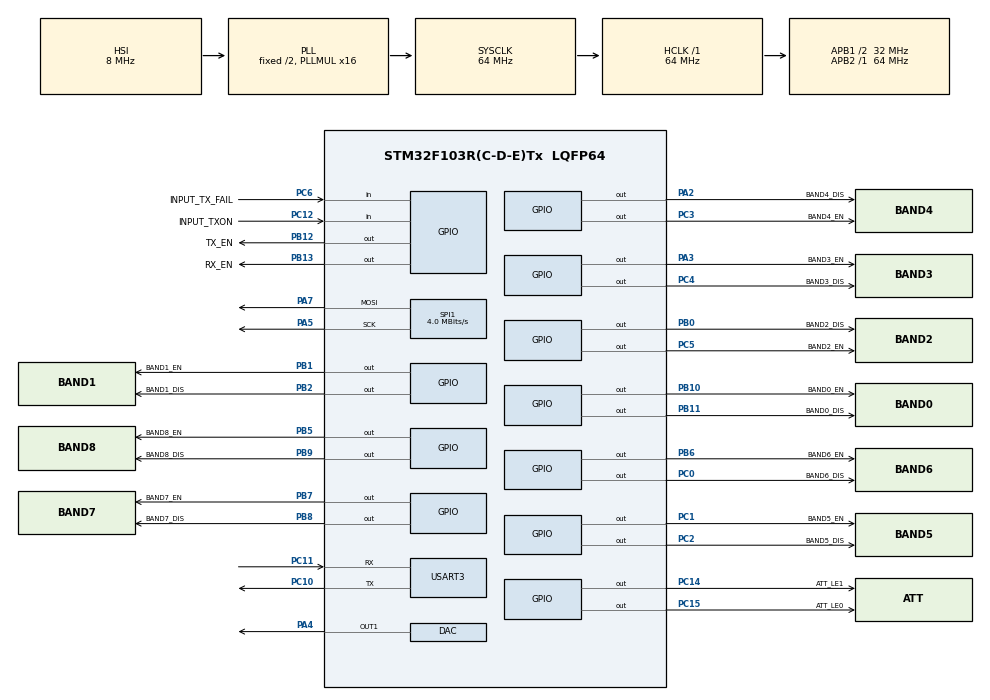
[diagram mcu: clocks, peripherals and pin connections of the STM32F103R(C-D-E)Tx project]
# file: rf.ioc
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Dma.Request0=USART3_RX
Dma.Request1=USART3_TX
Dma.USART3_RX.0.Direction=DMA_PERIPH_TO_MEMORY
Dma.USART3_RX.0.Instance=DMA1_Channel3
Dma.USART3_RX.0.MemDataAlignment=DMA_MDATAALIGN_BYTE
Dma.USART3_RX.0.MemInc=DMA_MINC_ENABLE
Dma.USART3_RX.0.Mode=DMA_CIRCULAR
Dma.USART3_RX.0.PeriphDataAlignment=DMA_PDATAALIGN_BYTE
Dma.USART3_RX.0.PeriphInc=DMA_PINC_DISABLE
Dma.USART3_RX.0.Priority=DMA_PRIORITY_LOW
Dma.USART3_TX.1.Direction=DMA_MEMORY_TO_PERIPH
Dma.USART3_TX.1.Instance=DMA1_Channel2
Dma.USART3_TX.1.MemDataAlignment=DMA_MDATAALIGN_BYTE
Dma.USART3_TX.1.MemInc=DMA_MINC_ENABLE
Dma.USART3_TX.1.Mode=DMA_NORMAL
Dma.USART3_TX.1.PeriphDataAlignment=DMA_PDATAALIGN_BYTE
Dma.USART3_TX.1.PeriphInc=DMA_PINC_DISABLE
Dma.USART3_TX.1.Priority=DMA_PRIORITY_LOW
Mcu.Family=STM32F1
Mcu.Name=STM32F103R(C-D-E)Tx
Mcu.Package=LQFP64
NVIC.DMA1_Channel2_IRQn=true\:7\:0\:true\:false\:true\:false\:true\:true
NVIC.DMA1_Channel3_IRQn=true\:7\:0\:true\:false\:true\:false\:true\:true
NVIC.PriorityGroup=NVIC_PRIORITYGROUP_4
NVIC.SPI1_IRQn=true\:6\:0\:true\:false\:true\:true\:true\:true
PA13.Mode=Trace_Asynchronous_SW
PA13.Signal=SYS_JTMS-SWDIO
PA14.Mode=Trace_Asynchronous_SW
PA14.Signal=SYS_JTCK-SWCLK
PA2.GPIO_Label=BAND4_DIS
PA2.Signal=GPIO_Output
PA3.GPIO_Label=BAND3_EN
PA3.Signal=GPIO_Output
PA4.Signal=COMP_DAC1_group
PA5.Mode=TX_Only_Simplex_Unidirect_Master
PA5.Signal=SPI1_SCK
PA7.Mode=TX_Only_Simplex_Unidirect_Master
PA7.Signal=SPI1_MOSI
PB0.GPIO_Label=BAND2_DIS
PB0.Signal=GPIO_Output
PB1.GPIO_Label=BAND1_EN
PB1.Signal=GPIO_Output
PB10.GPIO_Label=BAND0_EN
PB10.Signal=GPIO_Output
PB11.GPIO_Label=BAND0_DIS
PB11.Signal=GPIO_Output
PB12.GPIO_Label=TX_EN
PB12.GPIO_Speed=GPIO_SPEED_FREQ_HIGH
PB12.Signal=GPIO_Output
PB13.GPIO_Label=RX_EN
PB13.GPIO_Speed=GPIO_SPEED_FREQ_HIGH
PB13.Signal=GPIO_Output
PB2.GPIO_Label=BAND1_DIS
PB2.Signal=GPIO_Output
PB3.Mode=Trace_Asynchronous_SW
PB3.Signal=SYS_JTDO-TRACESWO
PB5.GPIO_Label=BAND8_EN
PB5.Signal=GPIO_Output
PB6.GPIO_Label=BAND6_EN
PB6.Signal=GPIO_Output
PB7.GPIO_Label=BAND7_EN
PB7.Signal=GPIO_Output
PB8.GPIO_Label=BAND7_DIS
PB8.Signal=GPIO_Output
PB9.GPIO_Label=BAND8_DIS
PB9.Signal=GPIO_Output
PC0.GPIO_Label=BAND6_DIS
PC0.Signal=GPIO_Output
PC1.GPIO_Label=BAND5_EN
PC1.Signal=GPIO_Output
PC10.Mode=Asynchronous
PC10.Signal=USART3_TX
PC11.Mode=Asynchronous
PC11.Signal=USART3_RX
PC12.GPIO_Label=INPUT_TXON
PC12.GPIO_PuPd=GPIO_PULLDOWN
PC12.Signal=GPIO_Input
PC14-OSC32_IN.GPIO_Label=ATT_LE1
PC14-OSC32_IN.GPIO_Speed=GPIO_SPEED_FREQ_HIGH
PC14-OSC32_IN.Signal=GPIO_Output
PC15-OSC32_OUT.GPIO_Label=ATT_LE0
PC15-OSC32_OUT.GPIO_Speed=GPIO_SPEED_FREQ_HIGH
PC15-OSC32_OUT.Signal=GPIO_Output
PC2.GPIO_Label=BAND5_DIS
PC2.Signal=GPIO_Output
PC3.GPIO_Label=BAND4_EN
PC3.Signal=GPIO_Output
PC4.GPIO_Label=BAND3_DIS
PC4.Signal=GPIO_Output
PC5.GPIO_Label=BAND2_EN
PC5.Signal=GPIO_Output
PC6.GPIO_Label=INPUT_TX_FAIL
PC6.GPIO_PuPd=GPIO_PULLDOWN
PC6.Signal=GPIO_Input
ProjectManager.HeapSize=0x200
ProjectManager.StackSize=0x400
ProjectManager.TargetToolchain=STM32CubeIDE
RCC.AHBFreq_Value=64000000
RCC.APB1CLKDivider=RCC_HCLK_DIV2
RCC.APB1Freq_Value=32000000
RCC.APB1TimFreq_Value=64000000
RCC.APB2Freq_Value=64000000
RCC.APB2TimFreq_Value=64000000
RCC.HCLKFreq_Value=64000000
RCC.PLLMUL=RCC_PLL_MUL16
RCC.SYSCLKFreq_VALUE=64000000
RCC.SYSCLKSource=RCC_SYSCLKSOURCE_PLLCLK
RCC.USBFreq_Value=64000000
SH.COMP_DAC1_group.0=DAC_OUT1,DAC_OUT1
SPI1.BaudRatePrescaler=SPI_BAUDRATEPRESCALER_16
SPI1.CalculateBaudRate=4.0 MBits/s
SPI1.Direction=SPI_DIRECTION_2LINES
SPI1.Mode=SPI_MODE_MASTER
SPI1.VirtualType=VM_MASTER
USART3.VirtualMode=VM_ASYNC
board=custom

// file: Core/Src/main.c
/* USER CODE BEGIN Header */
/**
  ******************************************************************************
  * @file           : main.c
  * @brief          : Main program body
  ******************************************************************************
  * @attention
  *
  * Copyright (c) 2025 STMicroelectronics.
  * All rights reserved.
  *
  * This software is licensed under terms that can be found in the LICENSE file
  * in the root directory of this software component.
  * If no LICENSE file comes with this software, it is provided AS-IS.
  *
  ******************************************************************************
  */
/* USER CODE END Header */
#include "main.h"

/* USER CODE BEGIN Includes */
#include "cmd.h"
#include "gpio.h"
/* USER CODE END Includes */

DAC_HandleTypeDef hdac;

SPI_HandleTypeDef hspi1;

UART_HandleTypeDef huart3;
DMA_HandleTypeDef hdma_usart3_rx;
DMA_HandleTypeDef hdma_usart3_tx;

void SystemClock_Config(void);
static void MX_GPIO_Init(void);
static void MX_DMA_Init(void);
static void MX_DAC_Init(void);
static void MX_SPI1_Init(void);
static void MX_USART3_UART_Init(void);

int main(void)
{

  /* MCU Configuration--------------------------------------------------------*/

  /* Reset of all peripherals, Initializes the Flash interface and the Systick. */
  HAL_Init();

  /* Configure the system clock */
  SystemClock_Config();

  /* Initialize all configured peripherals */
  MX_GPIO_Init();
  MX_DMA_Init();
  MX_DAC_Init();
  MX_SPI1_Init();
  MX_USART3_UART_Init();
  /* USER CODE BEGIN 2 */
  HAL_DAC_SetValue(&hdac, DAC_CHANNEL_1, DAC_ALIGN_12B_R, 0);
  HAL_DAC_Start(&hdac, DAC_CHANNEL_1);
  gpio_tx_off();
  cmd_start();
  /* USER CODE END 2 */

  /* Infinite loop */
  while (1)
  {

    /* USER CODE BEGIN 3 */
	  cmd_tick();
	  gpio_tick();
  }
  /* USER CODE END 3 */
}

void SystemClock_Config(void)
{
  RCC_OscInitTypeDef RCC_OscInitStruct = {0};
  RCC_ClkInitTypeDef RCC_ClkInitStruct = {0};

  /** Initializes the RCC Oscillators according to the specified parameters
  * in the RCC_OscInitTypeDef structure.
  */
  RCC_OscInitStruct.OscillatorType = RCC_OSCILLATORTYPE_HSI;
  RCC_OscInitStruct.HSIState = RCC_HSI_ON;
  RCC_OscInitStruct.HSICalibrationValue = RCC_HSICALIBRATION_DEFAULT;
  RCC_OscInitStruct.PLL.PLLState = RCC_PLL_ON;
  RCC_OscInitStruct.PLL.PLLSource = RCC_PLLSOURCE_HSI_DIV2;
  RCC_OscInitStruct.PLL.PLLMUL = RCC_PLL_MUL16;
  if (HAL_RCC_OscConfig(&RCC_OscInitStruct) != HAL_OK)
  {
    Error_Handler();
  }

  /** Initializes the CPU, AHB and APB buses clocks
  */
  RCC_ClkInitStruct.ClockType = RCC_CLOCKTYPE_HCLK|RCC_CLOCKTYPE_SYSCLK
                              |RCC_CLOCKTYPE_PCLK1|RCC_CLOCKTYPE_PCLK2;
  RCC_ClkInitStruct.SYSCLKSource = RCC_SYSCLKSOURCE_PLLCLK;
  RCC_ClkInitStruct.AHBCLKDivider = RCC_SYSCLK_DIV1;
  RCC_ClkInitStruct.APB1CLKDivider = RCC_HCLK_DIV2;
  RCC_ClkInitStruct.APB2CLKDivider = RCC_HCLK_DIV1;

  if (HAL_RCC_ClockConfig(&RCC_ClkInitStruct, FLASH_LATENCY_2) != HAL_OK)
  {
    Error_Handler();
  }
}

static void MX_DAC_Init(void)
{

  DAC_ChannelConfTypeDef sConfig = {0};

  /** DAC Initialization
  */
  hdac.Instance = DAC;
  if (HAL_DAC_Init(&hdac) != HAL_OK)
  {
    Error_Handler();
  }

  /** DAC channel OUT1 config
  */
  sConfig.DAC_Trigger = DAC_TRIGGER_NONE;
  sConfig.DAC_OutputBuffer = DAC_OUTPUTBUFFER_ENABLE;
  if (HAL_DAC_ConfigChannel(&hdac, &sConfig, DAC_CHANNEL_1) != HAL_OK)
  {
    Error_Handler();
  }

}

static void MX_SPI1_Init(void)
{

  /* SPI1 parameter configuration*/
  hspi1.Instance = SPI1;
  hspi1.Init.Mode = SPI_MODE_MASTER;
  hspi1.Init.Direction = SPI_DIRECTION_2LINES;
  hspi1.Init.DataSize = SPI_DATASIZE_8BIT;
  hspi1.Init.CLKPolarity = SPI_POLARITY_LOW;
  hspi1.Init.CLKPhase = SPI_PHASE_1EDGE;
  hspi1.Init.NSS = SPI_NSS_SOFT;
  hspi1.Init.BaudRatePrescaler = SPI_BAUDRATEPRESCALER_16;
  hspi1.Init.FirstBit = SPI_FIRSTBIT_MSB;
  hspi1.Init.TIMode = SPI_TIMODE_DISABLE;
  hspi1.Init.CRCCalculation = SPI_CRCCALCULATION_DISABLE;
  hspi1.Init.CRCPolynomial = 10;
  if (HAL_SPI_Init(&hspi1) != HAL_OK)
  {
    Error_Handler();
  }

}

static void MX_USART3_UART_Init(void)
{

  huart3.Instance = USART3;
  huart3.Init.BaudRate = 115200;
  huart3.Init.WordLength = UART_WORDLENGTH_8B;
  huart3.Init.StopBits = UART_STOPBITS_1;
  huart3.Init.Parity = UART_PARITY_NONE;
  huart3.Init.Mode = UART_MODE_TX_RX;
  huart3.Init.HwFlowCtl = UART_HWCONTROL_NONE;
  huart3.Init.OverSampling = UART_OVERSAMPLING_16;
  if (HAL_UART_Init(&huart3) != HAL_OK)
  {
    Error_Handler();
  }

}

static void MX_DMA_Init(void)
{

  /* DMA controller clock enable */
  __HAL_RCC_DMA1_CLK_ENABLE();

  /* DMA interrupt init */
  /* DMA1_Channel2_IRQn interrupt configuration */
  HAL_NVIC_SetPriority(DMA1_Channel2_IRQn, 7, 0);
  HAL_NVIC_EnableIRQ(DMA1_Channel2_IRQn);
  /* DMA1_Channel3_IRQn interrupt configuration */
  HAL_NVIC_SetPriority(DMA1_Channel3_IRQn, 7, 0);
  HAL_NVIC_EnableIRQ(DMA1_Channel3_IRQn);

}

static void MX_GPIO_Init(void)
{
  GPIO_InitTypeDef GPIO_InitStruct = {0};

  /* GPIO Ports Clock Enable */
  __HAL_RCC_GPIOC_CLK_ENABLE();
  __HAL_RCC_GPIOA_CLK_ENABLE();
  __HAL_RCC_GPIOB_CLK_ENABLE();

  /*Configure GPIO pin Output Level */
  HAL_GPIO_WritePin(GPIOC, ATT_LE1_Pin|ATT_LE0_Pin|BAND6_DIS_Pin|BAND5_EN_Pin
                          |BAND5_DIS_Pin|BAND4_EN_Pin|BAND3_DIS_Pin|BAND2_EN_Pin, GPIO_PIN_RESET);

  /*Configure GPIO pin Output Level */
  HAL_GPIO_WritePin(GPIOA, BAND4_DIS_Pin|BAND3_EN_Pin, GPIO_PIN_RESET);

  /*Configure GPIO pin Output Level */
  HAL_GPIO_WritePin(GPIOB, BAND2_DIS_Pin|BAND1_EN_Pin|BAND1_DIS_Pin|BAND0_EN_Pin
                          |BAND0_DIS_Pin|TX_EN_Pin|RX_EN_Pin|BAND8_EN_Pin
                          |BAND6_EN_Pin|BAND7_EN_Pin|BAND7_DIS_Pin|BAND8_DIS_Pin, GPIO_PIN_RESET);

  /*Configure GPIO pins : ATT_LE1_Pin ATT_LE0_Pin BAND6_DIS_Pin BAND5_EN_Pin
                           BAND5_DIS_Pin BAND4_EN_Pin BAND3_DIS_Pin BAND2_EN_Pin */
  GPIO_InitStruct.Pin = ATT_LE1_Pin|ATT_LE0_Pin|BAND6_DIS_Pin|BAND5_EN_Pin
                          |BAND5_DIS_Pin|BAND4_EN_Pin|BAND3_DIS_Pin|BAND2_EN_Pin;
  GPIO_InitStruct.Mode = GPIO_MODE_OUTPUT_PP;
  GPIO_InitStruct.Pull = GPIO_NOPULL;
  GPIO_InitStruct.Speed = GPIO_SPEED_FREQ_LOW;
  HAL_GPIO_Init(GPIOC, &GPIO_InitStruct);

  /*Configure GPIO pins : BAND4_DIS_Pin BAND3_EN_Pin */
  GPIO_InitStruct.Pin = BAND4_DIS_Pin|BAND3_EN_Pin;
  GPIO_InitStruct.Mode = GPIO_MODE_OUTPUT_PP;
  GPIO_InitStruct.Pull = GPIO_NOPULL;
  GPIO_InitStruct.Speed = GPIO_SPEED_FREQ_LOW;
  HAL_GPIO_Init(GPIOA, &GPIO_InitStruct);

  /*Configure GPIO pins : BAND2_DIS_Pin BAND1_EN_Pin BAND1_DIS_Pin BAND0_EN_Pin
                           BAND0_DIS_Pin TX_EN_Pin RX_EN_Pin BAND8_EN_Pin
                           BAND6_EN_Pin BAND7_EN_Pin BAND7_DIS_Pin BAND8_DIS_Pin */
  GPIO_InitStruct.Pin = BAND2_DIS_Pin|BAND1_EN_Pin|BAND1_DIS_Pin|BAND0_EN_Pin
                          |BAND0_DIS_Pin|TX_EN_Pin|RX_EN_Pin|BAND8_EN_Pin
                          |BAND6_EN_Pin|BAND7_EN_Pin|BAND7_DIS_Pin|BAND8_DIS_Pin;
  GPIO_InitStruct.Mode = GPIO_MODE_OUTPUT_PP;
  GPIO_InitStruct.Pull = GPIO_NOPULL;
  GPIO_InitStruct.Speed = GPIO_SPEED_FREQ_LOW;
  HAL_GPIO_Init(GPIOB, &GPIO_InitStruct);

  /*Configure GPIO pins : INPUT_TX_FAIL_Pin INPUT_TXON_Pin */
  GPIO_InitStruct.Pin = INPUT_TX_FAIL_Pin|INPUT_TXON_Pin;
  GPIO_InitStruct.Mode = GPIO_MODE_INPUT;
  GPIO_InitStruct.Pull = GPIO_PULLDOWN;
  HAL_GPIO_Init(GPIOC, &GPIO_InitStruct);

}

void Error_Handler(void)
{
  __disable_irq();
  while (1)
  {
  }
}
